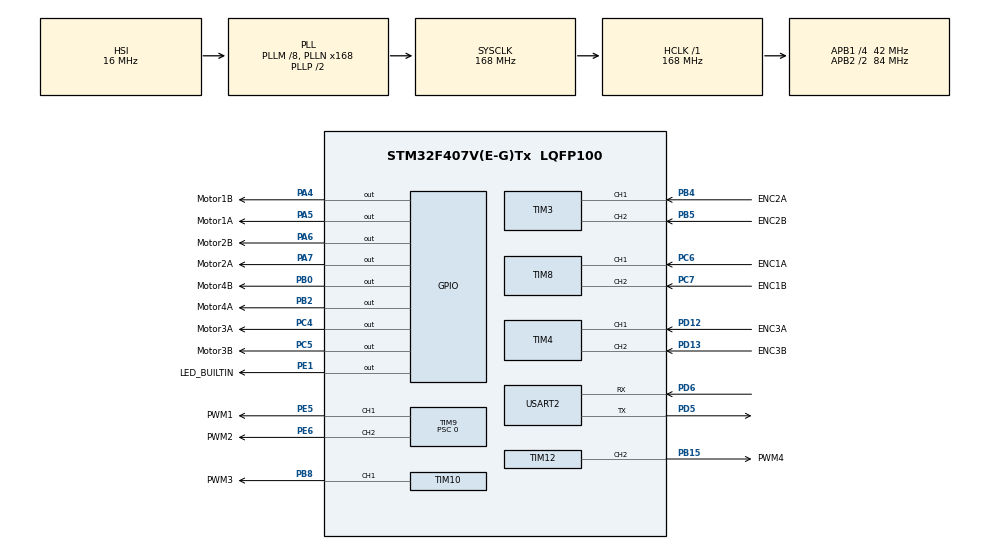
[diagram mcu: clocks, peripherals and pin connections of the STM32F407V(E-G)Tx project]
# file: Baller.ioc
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Dma.Request0=USART2_RX
Dma.USART2_RX.0.Direction=DMA_PERIPH_TO_MEMORY
Dma.USART2_RX.0.FIFOMode=DMA_FIFOMODE_DISABLE
Dma.USART2_RX.0.Instance=DMA1_Stream5
Dma.USART2_RX.0.MemDataAlignment=DMA_MDATAALIGN_BYTE
Dma.USART2_RX.0.MemInc=DMA_MINC_ENABLE
Dma.USART2_RX.0.Mode=DMA_CIRCULAR
Dma.USART2_RX.0.PeriphDataAlignment=DMA_PDATAALIGN_BYTE
Dma.USART2_RX.0.PeriphInc=DMA_PINC_DISABLE
Dma.USART2_RX.0.Priority=DMA_PRIORITY_LOW
Mcu.Family=STM32F4
Mcu.Name=STM32F407V(E-G)Tx
Mcu.Package=LQFP100
NVIC.DMA1_Stream5_IRQn=true\:0\:0\:false\:false\:true\:false\:true\:true
NVIC.PriorityGroup=NVIC_PRIORITYGROUP_4
NVIC.TIM2_IRQn=true\:0\:0\:false\:false\:true\:true\:true\:true
NVIC.USART2_IRQn=true\:0\:0\:false\:false\:true\:true\:true\:true
PA4.GPIO_Label=Motor1B
PA4.Signal=GPIO_Output
PA5.GPIO_Label=Motor1A
PA5.Signal=GPIO_Output
PA6.GPIO_Label=Motor2B
PA6.Signal=GPIO_Output
PA7.GPIO_Label=Motor2A
PA7.Signal=GPIO_Output
PB0.GPIO_Label=Motor4B
PB0.Signal=GPIO_Output
PB15.GPIO_Label=PWM4
PB15.Signal=S_TIM12_CH2
PB2.GPIO_Label=Motor4A
PB2.Signal=GPIO_Output
PB4.GPIO_Label=ENC2A
PB4.GPIO_PuPd=GPIO_PULLUP
PB4.Signal=S_TIM3_CH1
PB5.GPIO_Label=ENC2B
PB5.GPIO_PuPd=GPIO_PULLUP
PB5.Signal=S_TIM3_CH2
PB8.GPIO_Label=PWM3
PB8.Signal=S_TIM10_CH1
PC4.GPIO_Label=Motor3A
PC4.Signal=GPIO_Output
PC5.GPIO_Label=Motor3B
PC5.Signal=GPIO_Output
PC6.GPIO_Label=ENC1A
PC6.GPIO_PuPd=GPIO_PULLUP
PC6.Signal=S_TIM8_CH1
PC7.GPIO_Label=ENC1B
PC7.GPIO_PuPd=GPIO_PULLUP
PC7.Signal=S_TIM8_CH2
PD12.GPIO_Label=ENC3A
PD12.GPIO_PuPd=GPIO_PULLUP
PD12.Signal=S_TIM4_CH1
PD13.GPIO_Label=ENC3B
PD13.GPIO_ModeDefaultPP=GPIO_MODE_AF_PP
PD13.GPIO_PuPd=GPIO_PULLUP
PD13.Signal=S_TIM4_CH2
PD5.Mode=Asynchronous
PD5.Signal=USART2_TX
PD6.Mode=Asynchronous
PD6.Signal=USART2_RX
PE1.GPIO_Label=LED_BUILTIN
PE1.Signal=GPIO_Output
PE5.GPIO_Label=PWM1
PE5.Signal=S_TIM9_CH1
PE6.GPIO_Label=PWM2
PE6.Signal=S_TIM9_CH2
ProjectManager.HeapSize=0x200
ProjectManager.StackSize=0x400
ProjectManager.TargetToolchain=CMake
RCC.48MHZClocksFreq_Value=84000000
RCC.AHBFreq_Value=168000000
RCC.APB1CLKDivider=RCC_HCLK_DIV4
RCC.APB1Freq_Value=42000000
RCC.APB1TimFreq_Value=84000000
RCC.APB2CLKDivider=RCC_HCLK_DIV2
RCC.APB2Freq_Value=84000000
RCC.APB2TimFreq_Value=168000000
RCC.CortexFreq_Value=168000000
RCC.HCLKFreq_Value=168000000
RCC.HSE_VALUE=25000000
RCC.HSI_VALUE=16000000
RCC.LSE_VALUE=32768
RCC.PLLM=8
RCC.PLLN=168
RCC.SYSCLKFreq_VALUE=168000000
RCC.SYSCLKSource=RCC_SYSCLKSOURCE_PLLCLK
RCC.VCOOutputFreq_Value=336000000
SH.S_TIM10_CH1.0=TIM10_CH1,PWM Generation1 CH1
SH.S_TIM12_CH2.0=TIM12_CH2,PWM Generation2 CH2
SH.S_TIM3_CH1.0=TIM3_CH1,Encoder_Interface
SH.S_TIM3_CH2.0=TIM3_CH2,Encoder_Interface
SH.S_TIM4_CH1.0=TIM4_CH1,Encoder_Interface
SH.S_TIM4_CH2.0=TIM4_CH2,Encoder_Interface
SH.S_TIM8_CH1.0=TIM8_CH1,Encoder_Interface
SH.S_TIM8_CH2.0=TIM8_CH2,Encoder_Interface
SH.S_TIM9_CH1.0=TIM9_CH1,PWM Generation1 CH1
SH.S_TIM9_CH2.0=TIM9_CH2,PWM Generation2 CH2
TIM10.AutoReloadPreload=TIM_AUTORELOAD_PRELOAD_ENABLE
TIM10.Channel=TIM_CHANNEL_1
TIM10.Period=16383
TIM12.AutoReloadPreload=TIM_AUTORELOAD_PRELOAD_ENABLE
TIM12.Channel-PWM\ Generation2\ CH2=TIM_CHANNEL_2
TIM12.Period=16383
TIM12.Prescaler=0
TIM2.AutoReloadPreload=TIM_AUTORELOAD_PRELOAD_ENABLE
TIM2.Prescaler=83
TIM3.Channel-PWM\ Generation4\ CH4=TIM_CHANNEL_4
TIM3.EncoderMode=TIM_ENCODERMODE_TI12
TIM4.EncoderMode=TIM_ENCODERMODE_TI12
TIM8.EncoderMode=TIM_ENCODERMODE_TI12
TIM9.AutoReloadPreload=TIM_AUTORELOAD_PRELOAD_ENABLE
TIM9.Channel-PWM\ Generation1\ CH1=TIM_CHANNEL_1
TIM9.Channel-PWM\ Generation2\ CH2=TIM_CHANNEL_2
TIM9.Period=16383
TIM9.Prescaler=0
USART2.VirtualMode=VM_ASYNC
VP_TIM10_VS_ClockSourceINT.Mode=Enable_Timer
VP_TIM12_VS_ClockSourceINT.Mode=Internal
VP_TIM2_VS_ClockSourceINT.Mode=Internal
VP_TIM9_VS_ClockSourceINT.Mode=Internal
board=custom

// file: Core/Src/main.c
/* USER CODE BEGIN Header */
/**
 ******************************************************************************
 * @file           : main.c
 * @brief          : Main program body
 ******************************************************************************
 * @attention
 *
 * Copyright (c) 2026 STMicroelectronics.
 * All rights reserved.
 *
 * This software is licensed under terms that can be found in the LICENSE file
 * in the root directory of this software component.
 * If no LICENSE file comes with this software, it is provided AS-IS.
 *
 ******************************************************************************
 */
/* USER CODE END Header */
#include "main.h"
#include "dma.h"
#include "gpio.h"
#include "tim.h"
#include "usart.h"

/* USER CODE BEGIN Includes */

#include "core.hpp"
/* USER CODE END Includes */

void SystemClock_Config(void);

int main(void) {

	/* MCU
	 * Configuration--------------------------------------------------------*/

	/* Reset of all peripherals, Initializes the Flash interface and the
	 * Systick. */
	HAL_Init();

	/* Configure the system clock */
	SystemClock_Config();

	/* Initialize all configured peripherals */
	MX_GPIO_Init();
	MX_DMA_Init();
	MX_TIM9_Init();
	MX_TIM12_Init();
	MX_USART2_UART_Init();
	MX_TIM3_Init();
	MX_TIM4_Init();
	MX_TIM8_Init();
	MX_TIM10_Init();
	MX_TIM2_Init();
	/* USER CODE BEGIN 2 */

	setup();
	/* USER CODE END 2 */

	/* Infinite loop */
	/* USER CODE BEGIN WHILE */
	while (1) {
		loop();
		/* USER CODE END WHILE */

	}
}

void SystemClock_Config(void) {
	RCC_OscInitTypeDef RCC_OscInitStruct = {0};
	RCC_ClkInitTypeDef RCC_ClkInitStruct = {0};

	/** Configure the main internal regulator output voltage
	 */
	__HAL_RCC_PWR_CLK_ENABLE();
	__HAL_PWR_VOLTAGESCALING_CONFIG(PWR_REGULATOR_VOLTAGE_SCALE1);

	/** Initializes the RCC Oscillators according to the specified parameters
	 * in the RCC_OscInitTypeDef structure.
	 */
	RCC_OscInitStruct.OscillatorType = RCC_OSCILLATORTYPE_HSI;
	RCC_OscInitStruct.HSIState = RCC_HSI_ON;
	RCC_OscInitStruct.HSICalibrationValue = RCC_HSICALIBRATION_DEFAULT;
	RCC_OscInitStruct.PLL.PLLState = RCC_PLL_ON;
	RCC_OscInitStruct.PLL.PLLSource = RCC_PLLSOURCE_HSI;
	RCC_OscInitStruct.PLL.PLLM = 8;
	RCC_OscInitStruct.PLL.PLLN = 168;
	RCC_OscInitStruct.PLL.PLLP = RCC_PLLP_DIV2;
	RCC_OscInitStruct.PLL.PLLQ = 4;
	if (HAL_RCC_OscConfig(&RCC_OscInitStruct) != HAL_OK) {
		Error_Handler();
	}

	/** Initializes the CPU, AHB and APB buses clocks
	 */
	RCC_ClkInitStruct.ClockType = RCC_CLOCKTYPE_HCLK | RCC_CLOCKTYPE_SYSCLK |
								  RCC_CLOCKTYPE_PCLK1 | RCC_CLOCKTYPE_PCLK2;
	RCC_ClkInitStruct.SYSCLKSource = RCC_SYSCLKSOURCE_PLLCLK;
	RCC_ClkInitStruct.AHBCLKDivider = RCC_SYSCLK_DIV1;
	RCC_ClkInitStruct.APB1CLKDivider = RCC_HCLK_DIV4;
	RCC_ClkInitStruct.APB2CLKDivider = RCC_HCLK_DIV2;

	if (HAL_RCC_ClockConfig(&RCC_ClkInitStruct, FLASH_LATENCY_5) != HAL_OK) {
		Error_Handler();
	}
}

void Error_Handler(void) {
	/* USER CODE BEGIN Error_Handler_Debug */
	/* User can add his own implementation to report the HAL error return state
	 */
	__disable_irq();
	while (1) {
	}
	/* USER CODE END Error_Handler_Debug */
}
#ifdef USE_FULL_ASSERT
/**
 * @brief  Reports the name of the source file and the source line number
 *         where the assert_param error has occurred.
 * @param  file: pointer to the source file name
 * @param  line: assert_param error line source number
 * @retval None
 */
void assert_failed(uint8_t *file, uint32_t line) {
	/* USER CODE BEGIN 6 */
	/* User can add his own implementation to report the file name and line
	   number, ex: printf("Wrong parameters value: file %s on line %d\r\n",
	   file, line) */
	/* USER CODE END 6 */
}
#endif /* USE_FULL_ASSERT */
